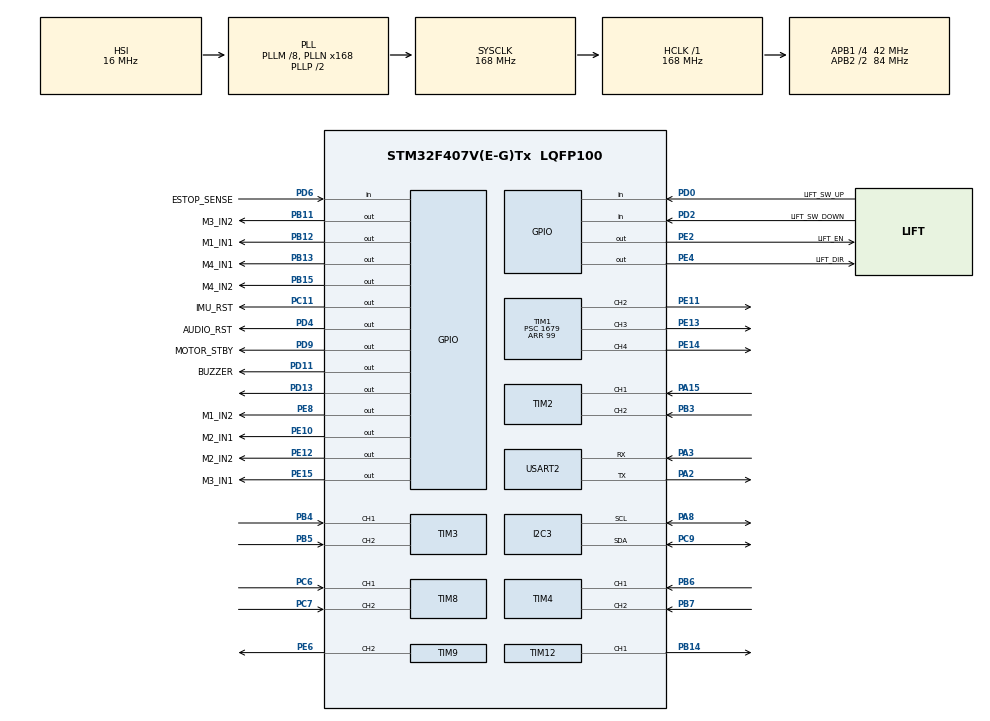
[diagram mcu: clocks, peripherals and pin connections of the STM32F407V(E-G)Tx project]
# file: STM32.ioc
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Dma.Request0=USART2_TX
Dma.USART2_TX.0.Direction=DMA_MEMORY_TO_PERIPH
Dma.USART2_TX.0.FIFOMode=DMA_FIFOMODE_DISABLE
Dma.USART2_TX.0.Instance=DMA1_Stream6
Dma.USART2_TX.0.MemDataAlignment=DMA_MDATAALIGN_BYTE
Dma.USART2_TX.0.MemInc=DMA_MINC_ENABLE
Dma.USART2_TX.0.Mode=DMA_NORMAL
Dma.USART2_TX.0.PeriphDataAlignment=DMA_PDATAALIGN_BYTE
Dma.USART2_TX.0.PeriphInc=DMA_PINC_DISABLE
Dma.USART2_TX.0.Priority=DMA_PRIORITY_LOW
FREERTOS.Tasks01=controlTask,24,256,StartControlTask,Default,NULL,Dynamic,NULL,NULL;logTask,16,512,StartLogTask,Default,NULL,Dynamic,NULL,NULL
FREERTOS.configCHECK_FOR_STACK_OVERFLOW=2
Mcu.Family=STM32F4
Mcu.Name=STM32F407V(E-G)Tx
Mcu.Package=LQFP100
NVIC.DMA1_Stream6_IRQn=true\:5\:0\:false\:false\:true\:true\:false\:true\:true
NVIC.PriorityGroup=NVIC_PRIORITYGROUP_4
NVIC.TIM7_IRQn=true\:15\:0\:false\:false\:true\:false\:false\:true\:true
NVIC.TimeBase=TIM7_IRQn
NVIC.TimeBaseIP=TIM7
NVIC.USART2_IRQn=true\:5\:0\:false\:false\:true\:true\:true\:true\:true
PA13.Mode=Serial_Wire
PA13.Signal=SYS_JTMS-SWDIO
PA14.Mode=Serial_Wire
PA14.Signal=SYS_JTCK-SWCLK
PA15.Signal=S_TIM2_CH1_ETR
PA2.Mode=Asynchronous
PA2.Signal=USART2_TX
PA3.Mode=Asynchronous
PA3.Signal=USART2_RX
PA8.Mode=I2C
PA8.Signal=I2C3_SCL
PB11.GPIO_Label=M3_IN2
PB11.Signal=GPIO_Output
PB12.GPIO_Label=M1_IN1
PB12.Signal=GPIO_Output
PB13.GPIO_Label=M4_IN1
PB13.Signal=GPIO_Output
PB14.Signal=S_TIM12_CH1
PB15.GPIO_Label=M4_IN2
PB15.Signal=GPIO_Output
PB3.Signal=S_TIM2_CH2
PB4.Signal=S_TIM3_CH1
PB5.Signal=S_TIM3_CH2
PB6.Signal=S_TIM4_CH1
PB7.Signal=S_TIM4_CH2
PC11.GPIO_Label=IMU_RST
PC11.PinState=GPIO_PIN_SET
PC11.Signal=GPIO_Output
PC6.Signal=S_TIM8_CH1
PC7.Signal=S_TIM8_CH2
PC9.Mode=I2C
PC9.Signal=I2C3_SDA
PD0.GPIO_Label=LIFT_SW_UP
PD0.GPIO_PuPd=GPIO_PULLUP
PD0.Signal=GPIO_Input
PD11.GPIO_Label=BUZZER
PD11.Signal=GPIO_Output
PD13.Signal=GPIO_Output
PD2.GPIO_Label=LIFT_SW_DOWN
PD2.GPIO_PuPd=GPIO_PULLUP
PD2.Signal=GPIO_Input
PD4.GPIO_Label=AUDIO_RST
PD4.Signal=GPIO_Output
PD6.GPIO_Label=ESTOP_SENSE
PD6.Signal=GPIO_Input
PD9.GPIO_Label=MOTOR_STBY
PD9.Signal=GPIO_Output
PE10.GPIO_Label=M2_IN1
PE10.Signal=GPIO_Output
PE11.Signal=S_TIM1_CH2
PE12.GPIO_Label=M2_IN2
PE12.Signal=GPIO_Output
PE13.Signal=S_TIM1_CH3
PE14.Signal=S_TIM1_CH4
PE15.GPIO_Label=M3_IN1
PE15.Signal=GPIO_Output
PE2.GPIO_Label=LIFT_EN
PE2.Signal=GPIO_Output
PE4.GPIO_Label=LIFT_DIR
PE4.Signal=GPIO_Output
PE6.Signal=S_TIM9_CH2
PE8.GPIO_Label=M1_IN2
PE8.Signal=GPIO_Output
PH0-OSC_IN.Mode=HSE-External-Oscillator
PH0-OSC_IN.Signal=RCC_OSC_IN
PH1-OSC_OUT.Mode=HSE-External-Oscillator
PH1-OSC_OUT.Signal=RCC_OSC_OUT
ProjectManager.HeapSize=0x200
ProjectManager.StackSize=0x400
ProjectManager.TargetToolchain=CMake
RCC.48MHZClocksFreq_Value=84000000
RCC.AHBFreq_Value=168000000
RCC.APB1CLKDivider=RCC_HCLK_DIV4
RCC.APB1Freq_Value=42000000
RCC.APB1TimFreq_Value=84000000
RCC.APB2CLKDivider=RCC_HCLK_DIV2
RCC.APB2Freq_Value=84000000
RCC.APB2TimFreq_Value=168000000
RCC.CortexFreq_Value=168000000
RCC.HCLKFreq_Value=168000000
RCC.HSE_VALUE=25000000
RCC.HSI_VALUE=16000000
RCC.LSE_VALUE=32768
RCC.PLLM=8
RCC.PLLN=168
RCC.SYSCLKFreq_VALUE=168000000
RCC.SYSCLKSource=RCC_SYSCLKSOURCE_PLLCLK
RCC.VCOOutputFreq_Value=336000000
SH.S_TIM12_CH1.0=TIM12_CH1,PWM Generation1 CH1
SH.S_TIM1_CH2.0=TIM1_CH2,PWM Generation2 CH2
SH.S_TIM1_CH3.0=TIM1_CH3,PWM Generation3 CH3
SH.S_TIM1_CH4.0=TIM1_CH4,PWM Generation4 CH4
SH.S_TIM2_CH1_ETR.0=TIM2_CH1,Encoder_Interface
SH.S_TIM2_CH2.0=TIM2_CH2,Encoder_Interface
SH.S_TIM3_CH1.0=TIM3_CH1,Encoder_Interface
SH.S_TIM3_CH2.0=TIM3_CH2,Encoder_Interface
SH.S_TIM4_CH1.0=TIM4_CH1,Encoder_Interface
SH.S_TIM4_CH2.0=TIM4_CH2,Encoder_Interface
SH.S_TIM8_CH1.0=TIM8_CH1,Encoder_Interface
SH.S_TIM8_CH2.0=TIM8_CH2,Encoder_Interface
SH.S_TIM9_CH2.0=TIM9_CH2,PWM Generation2 CH2
TIM1.AutoReloadPreload=TIM_AUTORELOAD_PRELOAD_ENABLE
TIM1.Channel-PWM\ Generation2\ CH2=TIM_CHANNEL_2
TIM1.Channel-PWM\ Generation3\ CH3=TIM_CHANNEL_3
TIM1.Channel-PWM\ Generation4\ CH4=TIM_CHANNEL_4
TIM1.Period=99
TIM1.Prescaler=1679
TIM12.AutoReloadPreload=TIM_AUTORELOAD_PRELOAD_ENABLE
TIM12.Channel-PWM\ Generation1\ CH1=TIM_CHANNEL_1
TIM12.Period=99
TIM12.Prescaler=839
TIM2.EncoderMode=TIM_ENCODERMODE_TI12
TIM2.IC1Filter=10
TIM2.IC2Filter=10
TIM3.EncoderMode=TIM_ENCODERMODE_TI12
TIM3.IC1Filter=10
TIM3.IC2Filter=10
TIM4.EncoderMode=TIM_ENCODERMODE_TI12
TIM4.IC1Filter=10
TIM4.IC2Filter=10
TIM8.EncoderMode=TIM_ENCODERMODE_TI12
TIM8.IC1Filter=10
TIM8.IC2Filter=10
TIM9.Channel-PWM\ Generation2\ CH2=TIM_CHANNEL_2
USART2.VirtualMode=VM_ASYNC
VP_FREERTOS_VS_CMSIS_V2.Mode=CMSIS_V2
VP_SYS_VS_tim7.Mode=TIM7
VP_TIM12_VS_ClockSourceINT.Mode=Internal
VP_TIM9_VS_ClockSourceINT.Mode=Internal
board=custom

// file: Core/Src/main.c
/* USER CODE BEGIN Header */
/**
  ******************************************************************************
  * @file           : main.c
  * @brief          : Main program body
  ******************************************************************************
  * @attention
  *
  * Copyright (c) 2026 STMicroelectronics.
  * All rights reserved.
  *
  * This software is licensed under terms that can be found in the LICENSE file
  * in the root directory of this software component.
  * If no LICENSE file comes with this software, it is provided AS-IS.
  *
  ******************************************************************************
  */
/* USER CODE END Header */
#include "main.h"
#include "cmsis_os.h"
#include "dma.h"
#include "i2c.h"
#include "tim.h"
#include "usart.h"
#include "gpio.h"

/* USER CODE BEGIN Includes */
#include "app.h"
/* USER CODE END Includes */

void SystemClock_Config(void);
void MX_FREERTOS_Init(void);

int main(void)
{

  /* MCU Configuration--------------------------------------------------------*/

  /* Reset of all peripherals, Initializes the Flash interface and the Systick. */
  HAL_Init();

  /* Configure the system clock */
  SystemClock_Config();

  /* Initialize all configured peripherals */
  MX_GPIO_Init();
  MX_DMA_Init();
  MX_TIM1_Init();
  MX_TIM3_Init();
  MX_USART2_UART_Init();
  MX_I2C3_Init();
  MX_TIM2_Init();
  MX_TIM4_Init();
  MX_TIM8_Init();
  MX_TIM9_Init();
  MX_TIM12_Init();
  /* USER CODE BEGIN 2 */
  App_Init();
  /* USER CODE END 2 */

  /* Init scheduler */
  osKernelInitialize();  /* Call init function for freertos objects (in cmsis_os2.c) */
  MX_FREERTOS_Init();

  /* Start scheduler */
  osKernelStart();

  /* We should never get here as control is now taken by the scheduler */

  /* Infinite loop */
  while (1)
  {

  }
}

void SystemClock_Config(void)
{
  RCC_OscInitTypeDef RCC_OscInitStruct = {0};
  RCC_ClkInitTypeDef RCC_ClkInitStruct = {0};

  /** Configure the main internal regulator output voltage
  */
  __HAL_RCC_PWR_CLK_ENABLE();
  __HAL_PWR_VOLTAGESCALING_CONFIG(PWR_REGULATOR_VOLTAGE_SCALE1);

  /** Initializes the RCC Oscillators according to the specified parameters
  * in the RCC_OscInitTypeDef structure.
  */
  RCC_OscInitStruct.OscillatorType = RCC_OSCILLATORTYPE_HSI;
  RCC_OscInitStruct.HSIState = RCC_HSI_ON;
  RCC_OscInitStruct.HSICalibrationValue = RCC_HSICALIBRATION_DEFAULT;
  RCC_OscInitStruct.PLL.PLLState = RCC_PLL_ON;
  RCC_OscInitStruct.PLL.PLLSource = RCC_PLLSOURCE_HSI;
  RCC_OscInitStruct.PLL.PLLM = 8;
  RCC_OscInitStruct.PLL.PLLN = 168;
  RCC_OscInitStruct.PLL.PLLP = RCC_PLLP_DIV2;
  RCC_OscInitStruct.PLL.PLLQ = 4;
  if (HAL_RCC_OscConfig(&RCC_OscInitStruct) != HAL_OK)
  {
    Error_Handler();
  }

  /** Initializes the CPU, AHB and APB buses clocks
  */
  RCC_ClkInitStruct.ClockType = RCC_CLOCKTYPE_HCLK|RCC_CLOCKTYPE_SYSCLK
                              |RCC_CLOCKTYPE_PCLK1|RCC_CLOCKTYPE_PCLK2;
  RCC_ClkInitStruct.SYSCLKSource = RCC_SYSCLKSOURCE_PLLCLK;
  RCC_ClkInitStruct.AHBCLKDivider = RCC_SYSCLK_DIV1;
  RCC_ClkInitStruct.APB1CLKDivider = RCC_HCLK_DIV4;
  RCC_ClkInitStruct.APB2CLKDivider = RCC_HCLK_DIV2;

  if (HAL_RCC_ClockConfig(&RCC_ClkInitStruct, FLASH_LATENCY_5) != HAL_OK)
  {
    Error_Handler();
  }
}

void HAL_TIM_PeriodElapsedCallback(TIM_HandleTypeDef *htim)
{
  if (htim->Instance == TIM7)
  {
    HAL_IncTick();
  }
}

void Error_Handler(void)
{
  __disable_irq();
  while (1)
  {
  }
}

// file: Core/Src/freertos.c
/* USER CODE BEGIN Header */
/**
  ******************************************************************************
  * File Name          : freertos.c
  * Description        : Code for freertos applications
  ******************************************************************************
  * @attention
  *
  * Copyright (c) 2026 STMicroelectronics.
  * All rights reserved.
  *
  * This software is licensed under terms that can be found in the LICENSE file
  * in the root directory of this software component.
  * If no LICENSE file comes with this software, it is provided AS-IS.
  *
  ******************************************************************************
  */
/* USER CODE END Header */

#include "FreeRTOS.h"
#include "task.h"
#include "main.h"
#include "cmsis_os.h"

/* USER CODE BEGIN Includes */
#include "app.h"

/* USER CODE END Includes */

/* Definitions for controlTask */
osThreadId_t controlTaskHandle;
const osThreadAttr_t controlTask_attributes = {
  .name = "controlTask",
  .stack_size = 256 * 4,
  .priority = (osPriority_t) osPriorityNormal,
};
/* Definitions for logTask */
osThreadId_t logTaskHandle;
const osThreadAttr_t logTask_attributes = {
  .name = "logTask",
  .stack_size = 512 * 4,
  .priority = (osPriority_t) osPriorityBelowNormal,
};

void StartControlTask(void *argument);
void StartLogTask(void *argument);

void MX_FREERTOS_Init(void); /* (MISRA C 2004 rule 8.1) */

/* Hook prototypes */
void vApplicationStackOverflowHook(xTaskHandle xTask, signed char *pcTaskName);

/* USER CODE BEGIN 4 */
void vApplicationStackOverflowHook(xTaskHandle xTask, signed char *pcTaskName)
{
   /* Run time stack overflow checking is performed if
   configCHECK_FOR_STACK_OVERFLOW is defined to 1 or 2. This hook function is
   called if a stack overflow is detected. */
  (void)xTask;
  (void)pcTaskName;  /* xem ten task bi tran trong debugger */
  Error_Handler();
}
/* USER CODE END 4 */

void MX_FREERTOS_Init(void) {

  /* USER CODE BEGIN RTOS_QUEUES */
  /* add queues, ... */
  App_RtosInit();
  /* USER CODE END RTOS_QUEUES */

  /* Create the thread(s) */
  /* creation of controlTask */
  controlTaskHandle = osThreadNew(StartControlTask, NULL, &controlTask_attributes);

  /* creation of logTask */
  logTaskHandle = osThreadNew(StartLogTask, NULL, &logTask_attributes);

}

void StartControlTask(void *argument)
{
  /* USER CODE BEGIN StartControlTask */
  App_ControlTask(argument);  /* khong bao gio return */
  /* USER CODE END StartControlTask */
}

void StartLogTask(void *argument)
{
  /* USER CODE BEGIN StartLogTask */
  App_LogTask(argument);  /* khong bao gio return */
  /* USER CODE END StartLogTask */
}
